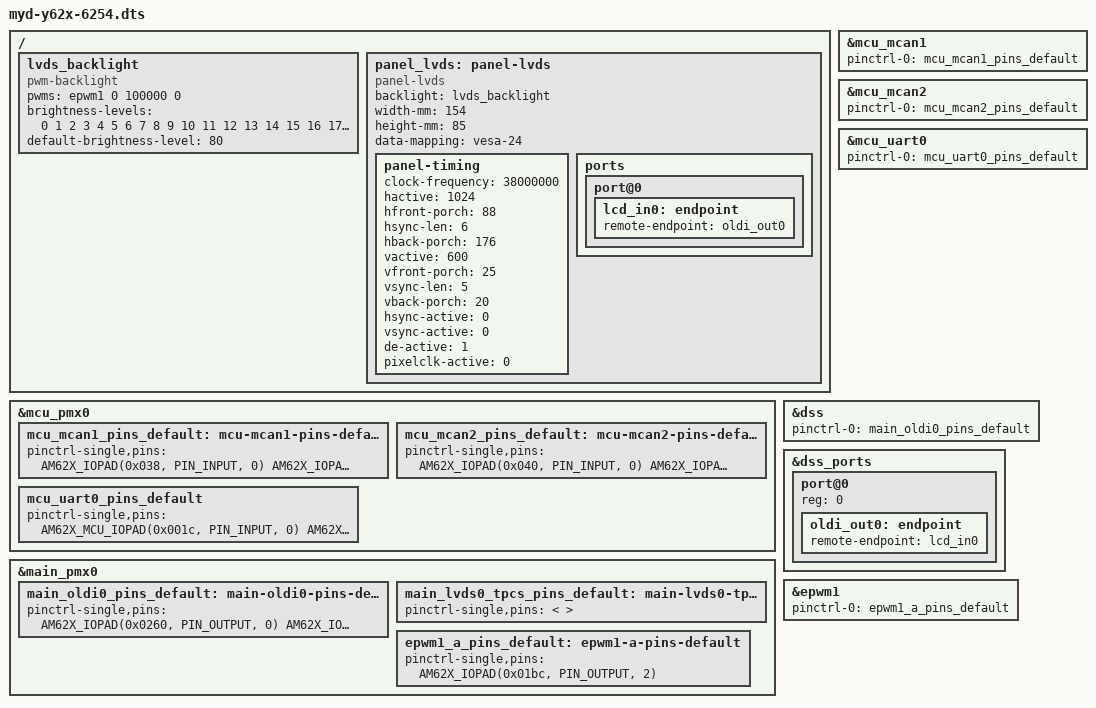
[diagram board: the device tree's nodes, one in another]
// SPDX-License-Identifier: GPL-2.0
/*
 * AM625 SK: https://www.ti.com/lit/zip/sprr448
 *
 * Copyright (C) 2021-2022 Texas Instruments Incorporated - https://www.ti.com/
 */

/dts-v1/;

#include <dt-bindings/leds/common.h>
#include <dt-bindings/gpio/gpio.h>
#include <dt-bindings/net/ti-dp83867.h>
#include "myd-y62x-common.dtsi"

/ {
    lvds_backlight: lvds_backlight {
        compatible = "pwm-backlight";
        pwms = <&epwm1 0 100000 0>;
        status = "okay";
        pinctrl-names = "default";
        brightness-levels = < 0  1  2  3  4  5  6  7  8  9
                        10 11 12 13 14 15 16 17 18 19
                        20 21 22 23 24 25 26 27 28 29
                        30 31 32 33 34 35 36 37 38 39
                        40 41 42 43 44 45 46 47 48 49
                        50 51 52 53 54 55 56 57 58 59
                        60 61 62 63 64 65 66 67 68 69
                        70 71 72 73 74 75 76 77 78 79
                        80 81 82 83 84 85 86 87 88 89
                        90 91 92 93 94 95 96 97 98 99
                    100>;
        default-brightness-level = <80>;
    };

			
    panel_lvds: panel-lvds {
        compatible = "panel-lvds";
        backlight = <&lvds_backlight>;

        width-mm = <154>;
        height-mm = <85>;
        data-mapping = "vesa-24";
        // data-mirror;
        panel-timing {
            clock-frequency = <38000000>;
            hactive = <1024>;
            hfront-porch = <88>;
            hsync-len = <6>;
            hback-porch = <176>;
                
            vactive = <600>;
            vfront-porch = <25>; 
            vsync-len = <5>;
            vback-porch = <20>;
            
            hsync-active = <0>;
            vsync-active = <0>;
            de-active = <1>;
            pixelclk-active = <0>;
        };

        ports {
            #address-cells = <1>;
            #size-cells = <0>;
            port@0 {
            
                lcd_in0: endpoint {
                    remote-endpoint = <&oldi_out0>;
                };
            };           
        };
	};
};

&mcu_pmx0 {
    mcu_mcan1_pins_default: mcu-mcan1-pins-default {
		pinctrl-single,pins = <
			AM62X_IOPAD(0x038, PIN_INPUT, 0) /* (B3) MCU_MCAN0_RX */
			AM62X_IOPAD(0x034, PIN_OUTPUT, 0) /* (D6) MCU_MCAN0_TX */
		>;
	};
	mcu_mcan2_pins_default: mcu-mcan2-pins-default {
		pinctrl-single,pins = <
			AM62X_IOPAD(0x040, PIN_INPUT, 0) /* (D4) MCU_MCAN1_RX */
			AM62X_IOPAD(0x03C, PIN_OUTPUT, 0) /* (E5) MCU_MCAN1_TX */
		>;
	};
    mcu_uart0_pins_default: mcu_uart0_pins_default {
		pinctrl-single,pins = <
            AM62X_MCU_IOPAD(0x001c, PIN_INPUT, 0) /* MCU_UART0_CTSn */
            AM62X_MCU_IOPAD(0x0020, PIN_OUTPUT, 0) /* MCU_UART0_RTSn */
            AM62X_MCU_IOPAD(0x0018, PIN_OUTPUT, 0) /* MCU_UART0_TXD */
        >;
	};
};
&mcu_mcan1 {
	pinctrl-names = "default";
	pinctrl-0 = <&mcu_mcan1_pins_default>;
	status = "okay";
};
//开mcan2需要关mcu_gpio0里面的mcu_run_led_pins_default,mcu_wlan_reg_on_pins_default引脚复用
&mcu_mcan2 {
	pinctrl-names = "default";
	pinctrl-0 = <&mcu_mcan2_pins_default>;
	status = "okay";
};
&mcu_uart0 {
	status = "okay";
	pinctrl-names = "default";
	pinctrl-0 = <&mcu_uart0_pins_default>;
};

&main_pmx0 {
	main_oldi0_pins_default: main-oldi0-pins-default {
		pinctrl-single,pins = <
			AM62X_IOPAD(0x0260, PIN_OUTPUT, 0) /* (AA5) OLDI0_A0N */
			AM62X_IOPAD(0x025c, PIN_OUTPUT, 0) /* (Y6) OLDI0_A0P */
			AM62X_IOPAD(0x0268, PIN_OUTPUT, 0) /* (AD3) OLDI0_A1N */
			AM62X_IOPAD(0x0264, PIN_OUTPUT, 0) /* (AB4) OLDI0_A1P */
			AM62X_IOPAD(0x0270, PIN_OUTPUT, 0) /* (Y8) OLDI0_A2N */
			AM62X_IOPAD(0x026c, PIN_OUTPUT, 0) /* (AA8) OLDI0_A2P */
			AM62X_IOPAD(0x0278, PIN_OUTPUT, 0) /* (AB6) OLDI0_A3N */
			AM62X_IOPAD(0x0274, PIN_OUTPUT, 0) /* (AA7) OLDI0_A3P */
			AM62X_IOPAD(0x0280, PIN_OUTPUT, 0) /* (AC6) OLDI0_A4N */
			AM62X_IOPAD(0x027c, PIN_OUTPUT, 0) /* (AC5) OLDI0_A4P */
			AM62X_IOPAD(0x02a0, PIN_OUTPUT, 0) /* (AD4) OLDI0_CLK0N */
			AM62X_IOPAD(0x029c, PIN_OUTPUT, 0) /* (AE3) OLDI0_CLK0P */
		>;
	};

	main_lvds0_tpcs_pins_default: main-lvds0-tpcs-pins-default {
		pinctrl-single,pins = <
			
		>;
	};
	
	epwm1_a_pins_default: epwm1-a-pins-default {
		pinctrl-single,pins = <
			AM62X_IOPAD(0x01bc, PIN_OUTPUT, 2) /* (A14) SPI0_CLK.EHRPWM1_A */
		>;
	};
};
&dss {
	pinctrl-names = "default";
	pinctrl-0 = <&main_oldi0_pins_default>;
	status = "okay";
};
&dss_ports {
	#address-cells = <1>;
	#size-cells = <0>;
    status = "okay";
	/* VP1: LVDS Output (OLDI TX 0) */
	port@0 {
		reg = <0>;
		oldi_out0: endpoint {
			remote-endpoint = <&lcd_in0>;
		};
	};
};
&epwm1 {
 	pinctrl-names = "default";
 	pinctrl-0 = <&epwm1_a_pins_default>;
 	status = "okay";
};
